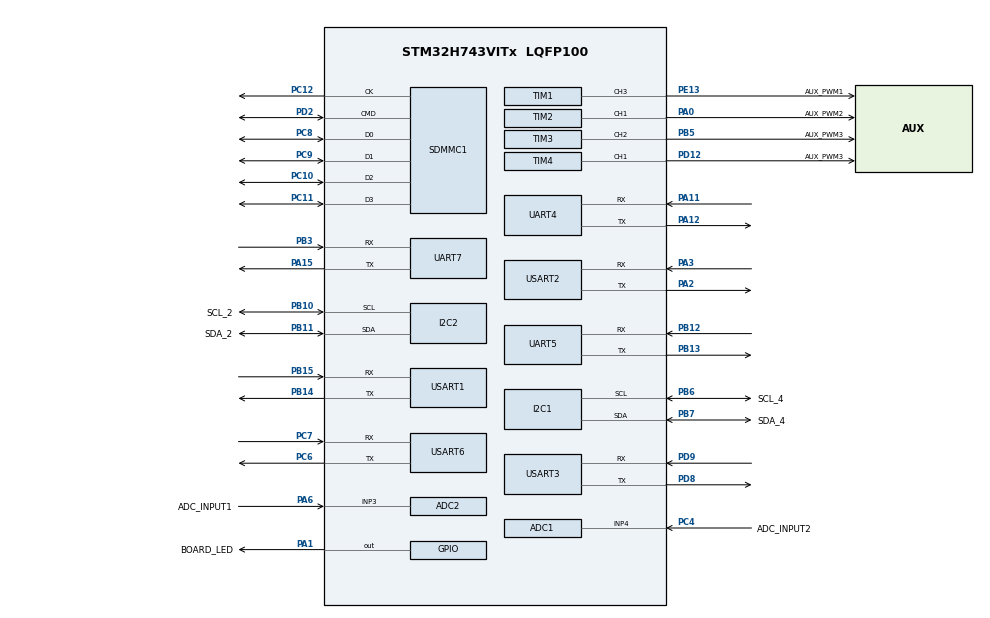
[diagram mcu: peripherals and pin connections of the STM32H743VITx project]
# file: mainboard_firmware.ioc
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ADC1.Channel-4\#ChannelRegularConversion=ADC_CHANNEL_4
ADC1.NbrOfConversionFlag=1
ADC1.OffsetNumber-4\#ChannelRegularConversion=ADC_OFFSET_NONE
ADC1.OffsetSignedSaturation-4\#ChannelRegularConversion=DISABLE
ADC1.Rank-4\#ChannelRegularConversion=1
ADC1.SamplingTime-4\#ChannelRegularConversion=ADC_SAMPLETIME_1CYCLE_5
ADC1.master=1
ADC2.Channel-1\#ChannelRegularConversion=ADC_CHANNEL_3
ADC2.NbrOfConversionFlag=1
ADC2.OffsetNumber-1\#ChannelRegularConversion=ADC_OFFSET_NONE
ADC2.OffsetSignedSaturation-1\#ChannelRegularConversion=DISABLE
ADC2.Rank-1\#ChannelRegularConversion=1
ADC2.SamplingTime-1\#ChannelRegularConversion=ADC_SAMPLETIME_1CYCLE_5
FATFS.USE_DMA_CODE_SD=0
I2C1.Timing=0x307075B1
I2C2.Timing=0x307075B1
Mcu.Family=STM32H7
Mcu.Name=STM32H743VITx
Mcu.Package=LQFP100
NVIC.PriorityGroup=NVIC_PRIORITYGROUP_4
NVIC.SDMMC1_IRQn=true\:0\:0\:false\:false\:true\:true\:true\:true
PA0.GPIO_Label=AUX_PWM2
PA0.Signal=S_TIM2_CH1_ETR
PA1.GPIO_Label=BOARD_LED
PA1.Signal=GPIO_Output
PA11.Mode=Asynchronous
PA11.Signal=UART4_RX
PA12.Mode=Asynchronous
PA12.Signal=UART4_TX
PA15\ (JTDI).Mode=Asynchronous
PA15\ (JTDI).Signal=UART7_TX
PA2.Mode=Asynchronous
PA2.Signal=USART2_TX
PA3.Mode=Asynchronous
PA3.Signal=USART2_RX
PA6.GPIO_Label=ADC_INPUT1
PA6.Signal=ADCx_INP3
PB10.GPIO_Label=SCL_2
PB10.Mode=I2C
PB10.Signal=I2C2_SCL
PB11.GPIO_Label=SDA_2
PB11.Mode=I2C
PB11.Signal=I2C2_SDA
PB12.Mode=Asynchronous
PB12.Signal=UART5_RX
PB13.Mode=Asynchronous
PB13.Signal=UART5_TX
PB14.Mode=Asynchronous
PB14.Signal=USART1_TX
PB15.Mode=Asynchronous
PB15.Signal=USART1_RX
PB3\ (JTDO/TRACESWO).Mode=Asynchronous
PB3\ (JTDO/TRACESWO).Signal=UART7_RX
PB5.GPIO_Label=AUX_PWM3
PB5.Signal=S_TIM3_CH2
PB6.GPIO_Label=SCL_4
PB6.Mode=I2C
PB6.Signal=I2C1_SCL
PB7.GPIO_Label=SDA_4
PB7.Mode=I2C
PB7.Signal=I2C1_SDA
PC10.Mode=SD_4_bits_Wide_bus
PC10.Signal=SDMMC1_D2
PC11.Mode=SD_4_bits_Wide_bus
PC11.Signal=SDMMC1_D3
PC12.Mode=SD_4_bits_Wide_bus
PC12.Signal=SDMMC1_CK
PC4.GPIO_Label=ADC_INPUT2
PC4.Signal=ADCx_INP4
PC6.Mode=Asynchronous
PC6.Signal=USART6_TX
PC7.Mode=Asynchronous
PC7.Signal=USART6_RX
PC8.Mode=SD_4_bits_Wide_bus
PC8.Signal=SDMMC1_D0
PC9.Mode=SD_4_bits_Wide_bus
PC9.Signal=SDMMC1_D1
PD12.GPIO_Label=AUX_PWM3
PD12.Signal=S_TIM4_CH1
PD2.Mode=SD_4_bits_Wide_bus
PD2.Signal=SDMMC1_CMD
PD8.Mode=Asynchronous
PD8.Signal=USART3_TX
PD9.Mode=Asynchronous
PD9.Signal=USART3_RX
PE13.GPIO_Label=AUX_PWM1
PE13.Signal=S_TIM1_CH3
PH0-OSC_IN\ (PH0).Mode=HSE-External-Oscillator
PH0-OSC_IN\ (PH0).Signal=RCC_OSC_IN
PH1-OSC_OUT\ (PH1).Mode=HSE-External-Oscillator
PH1-OSC_OUT\ (PH1).Signal=RCC_OSC_OUT
ProjectManager.HeapSize=0x200
ProjectManager.StackSize=0x400
ProjectManager.TargetToolchain=Makefile
RCC.ADCFreq_Value=10000000
RCC.APB1Freq_Value=120000000
RCC.APB2Freq_Value=120000000
RCC.APB3Freq_Value=120000000
RCC.APB4Freq_Value=120000000
RCC.CortexFreq_Value=480000000
RCC.D1PPRE=RCC_APB3_DIV2
RCC.D2PPRE1=RCC_APB1_DIV2
RCC.D2PPRE2=RCC_APB2_DIV2
RCC.D3PPRE=RCC_APB4_DIV2
RCC.DIVM1=5
RCC.DIVM2=5
RCC.DIVN1=192
RCC.DIVN2=40
RCC.DIVP2=20
RCC.DIVQ1=4
RCC.HCLKFreq_Value=240000000
RCC.HPRE=RCC_HCLK_DIV2
RCC.HSE_VALUE=25000000
RCC.PLL2FRACN=0
RCC.PLLSourceVirtual=RCC_PLLSOURCE_HSE
RCC.SYSCLKFreq_VALUE=480000000
RCC.SYSCLKSource=RCC_SYSCLKSOURCE_PLLCLK
RCC.USBFreq_Value=240000000
SH.ADCx_INP3.0=ADC2_INP3,IN3-Single-Ended
SH.ADCx_INP4.0=ADC1_INP4,IN4-Single-Ended
SH.S_TIM1_CH3.0=TIM1_CH3,PWM Generation3 CH3
SH.S_TIM2_CH1_ETR.0=TIM2_CH1,PWM Generation1 CH1
SH.S_TIM3_CH2.0=TIM3_CH2,PWM Generation2 CH2
SH.S_TIM4_CH1.0=TIM4_CH1,PWM Generation1 CH1
TIM1.Channel-PWM\ Generation3\ CH3=TIM_CHANNEL_3
TIM2.Channel-PWM\ Generation1\ CH1=TIM_CHANNEL_1
TIM3.Channel-PWM\ Generation2\ CH2=TIM_CHANNEL_2
TIM4.Channel-PWM\ Generation1\ CH1=TIM_CHANNEL_1
USART1.VirtualMode-Asynchronous=VM_ASYNC
USART2.VirtualMode-Asynchronous=VM_ASYNC
USART3.VirtualMode-Asynchronous=VM_ASYNC
USART6.VirtualMode=VM_ASYNC
VP_FATFS_VS_SDIO.Mode=SDIO
board=custom

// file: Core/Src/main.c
/* USER CODE BEGIN Header */
/**
  ******************************************************************************
  * @file           : main.c
  * @brief          : Main program body
  ******************************************************************************
  * @attention
  *
  * Copyright (c) 2022 STMicroelectronics.
  * All rights reserved.
  *
  * This software is licensed under terms that can be found in the LICENSE file
  * in the root directory of this software component.
  * If no LICENSE file comes with this software, it is provided AS-IS.
  *
  ******************************************************************************
  */
/* USER CODE END Header */
#include "main.h"
#include "adc.h"
#include "fatfs.h"
#include "i2c.h"
#include "sdmmc.h"
#include "tim.h"
#include "usart.h"
#include "gpio.h"

void SystemClock_Config(void);
void PeriphCommonClock_Config(void);

int main(void)
{

  /* MCU Configuration--------------------------------------------------------*/

  /* Reset of all peripherals, Initializes the Flash interface and the Systick. */
  HAL_Init();

  /* Configure the system clock */
  SystemClock_Config();

/* Configure the peripherals common clocks */
  PeriphCommonClock_Config();

  /* Initialize all configured peripherals */
  MX_GPIO_Init();
  MX_TIM1_Init();
  MX_TIM2_Init();
  MX_TIM3_Init();
  MX_TIM4_Init();
  MX_ADC1_Init();
  MX_ADC2_Init();
  MX_I2C1_Init();
  MX_I2C2_Init();
  MX_UART4_Init();
  MX_UART5_Init();
  MX_UART7_Init();
  MX_USART1_UART_Init();
  MX_USART2_UART_Init();
  MX_USART3_UART_Init();
  MX_USART6_UART_Init();
  MX_SDMMC1_SD_Init();
  MX_FATFS_Init();

  /* Infinite loop */
  /* USER CODE BEGIN WHILE */
  while (1)
  {
    HAL_GPIO_TogglePin(BOARD_LED_GPIO_Port, BOARD_LED_Pin);
    HAL_Delay(1000);
    /* USER CODE END WHILE */

  }
}

void SystemClock_Config(void)
{
  RCC_OscInitTypeDef RCC_OscInitStruct = {0};
  RCC_ClkInitTypeDef RCC_ClkInitStruct = {0};

  /** Supply configuration update enable
  */
  HAL_PWREx_ConfigSupply(PWR_LDO_SUPPLY);

  /** Configure the main internal regulator output voltage
  */
  __HAL_PWR_VOLTAGESCALING_CONFIG(PWR_REGULATOR_VOLTAGE_SCALE1);

  while(!__HAL_PWR_GET_FLAG(PWR_FLAG_VOSRDY)) {}

  __HAL_RCC_SYSCFG_CLK_ENABLE();
  __HAL_PWR_VOLTAGESCALING_CONFIG(PWR_REGULATOR_VOLTAGE_SCALE0);

  while(!__HAL_PWR_GET_FLAG(PWR_FLAG_VOSRDY)) {}

  /** Macro to configure the PLL clock source
  */
  __HAL_RCC_PLL_PLLSOURCE_CONFIG(RCC_PLLSOURCE_HSE);

  /** Initializes the RCC Oscillators according to the specified parameters
  * in the RCC_OscInitTypeDef structure.
  */
  RCC_OscInitStruct.OscillatorType = RCC_OSCILLATORTYPE_HSE;
  RCC_OscInitStruct.HSEState = RCC_HSE_ON;
  RCC_OscInitStruct.PLL.PLLState = RCC_PLL_ON;
  RCC_OscInitStruct.PLL.PLLSource = RCC_PLLSOURCE_HSE;
  RCC_OscInitStruct.PLL.PLLM = 5;
  RCC_OscInitStruct.PLL.PLLN = 192;
  RCC_OscInitStruct.PLL.PLLP = 2;
  RCC_OscInitStruct.PLL.PLLQ = 4;
  RCC_OscInitStruct.PLL.PLLR = 2;
  RCC_OscInitStruct.PLL.PLLRGE = RCC_PLL1VCIRANGE_2;
  RCC_OscInitStruct.PLL.PLLVCOSEL = RCC_PLL1VCOWIDE;
  RCC_OscInitStruct.PLL.PLLFRACN = 0;
  if (HAL_RCC_OscConfig(&RCC_OscInitStruct) != HAL_OK)
  {
    Error_Handler();
  }

  /** Initializes the CPU, AHB and APB buses clocks
  */
  RCC_ClkInitStruct.ClockType = RCC_CLOCKTYPE_HCLK|RCC_CLOCKTYPE_SYSCLK
                              |RCC_CLOCKTYPE_PCLK1|RCC_CLOCKTYPE_PCLK2
                              |RCC_CLOCKTYPE_D3PCLK1|RCC_CLOCKTYPE_D1PCLK1;
  RCC_ClkInitStruct.SYSCLKSource = RCC_SYSCLKSOURCE_PLLCLK;
  RCC_ClkInitStruct.SYSCLKDivider = RCC_SYSCLK_DIV1;
  RCC_ClkInitStruct.AHBCLKDivider = RCC_HCLK_DIV2;
  RCC_ClkInitStruct.APB3CLKDivider = RCC_APB3_DIV2;
  RCC_ClkInitStruct.APB1CLKDivider = RCC_APB1_DIV2;
  RCC_ClkInitStruct.APB2CLKDivider = RCC_APB2_DIV2;
  RCC_ClkInitStruct.APB4CLKDivider = RCC_APB4_DIV2;

  if (HAL_RCC_ClockConfig(&RCC_ClkInitStruct, FLASH_LATENCY_4) != HAL_OK)
  {
    Error_Handler();
  }
}

void PeriphCommonClock_Config(void)
{
  RCC_PeriphCLKInitTypeDef PeriphClkInitStruct = {0};

  /** Initializes the peripherals clock
  */
  PeriphClkInitStruct.PeriphClockSelection = RCC_PERIPHCLK_ADC;
  PeriphClkInitStruct.PLL2.PLL2M = 5;
  PeriphClkInitStruct.PLL2.PLL2N = 40;
  PeriphClkInitStruct.PLL2.PLL2P = 20;
  PeriphClkInitStruct.PLL2.PLL2Q = 2;
  PeriphClkInitStruct.PLL2.PLL2R = 2;
  PeriphClkInitStruct.PLL2.PLL2RGE = RCC_PLL2VCIRANGE_2;
  PeriphClkInitStruct.PLL2.PLL2VCOSEL = RCC_PLL2VCOWIDE;
  PeriphClkInitStruct.PLL2.PLL2FRACN = 0;
  PeriphClkInitStruct.AdcClockSelection = RCC_ADCCLKSOURCE_PLL2;
  if (HAL_RCCEx_PeriphCLKConfig(&PeriphClkInitStruct) != HAL_OK)
  {
    Error_Handler();
  }
}

void Error_Handler(void)
{
  __disable_irq();
  while (1)
  {
  }
}
